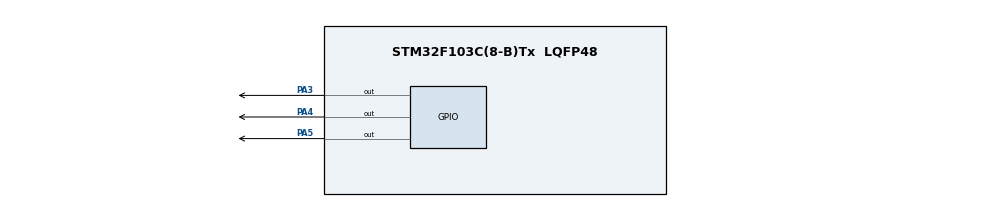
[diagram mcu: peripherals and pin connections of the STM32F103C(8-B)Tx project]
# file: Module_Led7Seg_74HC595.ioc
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Mcu.Family=STM32F1
Mcu.Name=STM32F103C(8-B)Tx
Mcu.Package=LQFP48
NVIC.PriorityGroup=NVIC_PRIORITYGROUP_4
PA13.Mode=Serial_Wire
PA13.Signal=SYS_JTMS-SWDIO
PA14.Mode=Serial_Wire
PA14.Signal=SYS_JTCK-SWCLK
PA3.Signal=GPIO_Output
PA4.Signal=GPIO_Output
PA5.Signal=GPIO_Output
ProjectManager.HeapSize=0x200
ProjectManager.StackSize=0x400
ProjectManager.TargetToolchain=STM32CubeIDE
RCC.APB1Freq_Value=8000000
RCC.APB2Freq_Value=8000000
board=custom

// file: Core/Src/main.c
/* USER CODE BEGIN Header */
/**
  ******************************************************************************
  * @file           : main.c
  * @brief          : Main program body
  ******************************************************************************
  * @attention
  *
  * Copyright (c) 2022 STMicroelectronics.
  * All rights reserved.
  *
  * This software is licensed under terms that can be found in the LICENSE file
  * in the root directory of this software component.
  * If no LICENSE file comes with this software, it is provided AS-IS.
  *
  ******************************************************************************
  */
/* USER CODE END Header */
#include "main.h"

/* USER CODE BEGIN PD */
#define CLK_GPIO GPIOA
#define CLK_PIN GPIO_PIN_3

#define LATCH_GPIO GPIOA
#define LATCH_PIN GPIO_PIN_4

#define DATA_GPIO GPIOA
#define DATA_PIN GPIO_PIN_5
/* USER CODE END PD */

void SystemClock_Config(void);
static void MX_GPIO_Init(void);

/* USER CODE BEGIN 0 */

int seg[10] = { 0x03, 0x9f, 0x25, 0x0D, 0x99, 0x49, 0x41, 0x1F, 0x01, 0x09 };
int seg_Dec[10] = { 0x02, 0x9E, 0x24, 0x0C, 0x98, 0x48, 0x40, 0x1E, 0x00, 0x08 };
int pos[8] = { 0x01, 0x02, 0x04, 0x08, 0x10, 0x20, 0x40, 0x80 };

void CLK()
{
	HAL_GPIO_WritePin(CLK_GPIO, CLK_PIN, GPIO_PIN_SET);
	HAL_GPIO_WritePin(CLK_GPIO, CLK_PIN, GPIO_PIN_RESET);
}

void LATCH()
{
	HAL_GPIO_WritePin(LATCH_GPIO, LATCH_PIN, GPIO_PIN_SET);
	HAL_GPIO_WritePin(LATCH_GPIO, LATCH_PIN, GPIO_PIN_RESET);
}

void DATA(int value)
{
	if(1==value)
	{
		HAL_GPIO_WritePin(DATA_GPIO, DATA_PIN, GPIO_PIN_SET);
	}
	else
	{
		HAL_GPIO_WritePin(DATA_GPIO, DATA_PIN, GPIO_PIN_RESET);
	}
	CLK();
}

void pushHEX(int hexValue)
{
	for (int i = 0; i < 8; i++) {
		if (hexValue & 0x01) {
			DATA(1);
		} else {
			DATA(0);
		}
		hexValue >>= 1;
	}
}

void shiftoutLed7Seg(int dataSeg, int position, int isDec) {
	position--;
	if (isDec == 1) {
		pushHEX(seg_Dec[dataSeg]);
		pushHEX(pos[position]);
		LATCH();
	} else {
		pushHEX(seg[dataSeg]);
		pushHEX(pos[position]);
		LATCH();
	}
}
/* USER CODE END 0 */

int main(void)
{

  /* MCU Configuration--------------------------------------------------------*/

  /* Reset of all peripherals, Initializes the Flash interface and the Systick. */
  HAL_Init();

  /* Configure the system clock */
  SystemClock_Config();

  /* Initialize all configured peripherals */
  MX_GPIO_Init();

  /* Infinite loop */
  /* USER CODE BEGIN WHILE */
  while (1)
  {
		shiftoutLed7Seg(2, 1, 0);
		shiftoutLed7Seg(7, 2, 0);
		shiftoutLed7Seg(1, 3, 0);
		shiftoutLed7Seg(0, 4, 0);
		shiftoutLed7Seg(2, 5, 0);
		shiftoutLed7Seg(0, 6, 0);
		shiftoutLed7Seg(0, 7, 0);
		shiftoutLed7Seg(0, 8, 0);
    /* USER CODE END WHILE */

  }
}

void SystemClock_Config(void)
{
  RCC_OscInitTypeDef RCC_OscInitStruct = {0};
  RCC_ClkInitTypeDef RCC_ClkInitStruct = {0};

  /** Initializes the RCC Oscillators according to the specified parameters
  * in the RCC_OscInitTypeDef structure.
  */
  RCC_OscInitStruct.OscillatorType = RCC_OSCILLATORTYPE_HSI;
  RCC_OscInitStruct.HSIState = RCC_HSI_ON;
  RCC_OscInitStruct.HSICalibrationValue = RCC_HSICALIBRATION_DEFAULT;
  RCC_OscInitStruct.PLL.PLLState = RCC_PLL_NONE;
  if (HAL_RCC_OscConfig(&RCC_OscInitStruct) != HAL_OK)
  {
    Error_Handler();
  }

  /** Initializes the CPU, AHB and APB buses clocks
  */
  RCC_ClkInitStruct.ClockType = RCC_CLOCKTYPE_HCLK|RCC_CLOCKTYPE_SYSCLK
                              |RCC_CLOCKTYPE_PCLK1|RCC_CLOCKTYPE_PCLK2;
  RCC_ClkInitStruct.SYSCLKSource = RCC_SYSCLKSOURCE_HSI;
  RCC_ClkInitStruct.AHBCLKDivider = RCC_SYSCLK_DIV1;
  RCC_ClkInitStruct.APB1CLKDivider = RCC_HCLK_DIV1;
  RCC_ClkInitStruct.APB2CLKDivider = RCC_HCLK_DIV1;

  if (HAL_RCC_ClockConfig(&RCC_ClkInitStruct, FLASH_LATENCY_0) != HAL_OK)
  {
    Error_Handler();
  }
}

static void MX_GPIO_Init(void)
{
  GPIO_InitTypeDef GPIO_InitStruct = {0};

  /* GPIO Ports Clock Enable */
  __HAL_RCC_GPIOA_CLK_ENABLE();

  /*Configure GPIO pin Output Level */
  HAL_GPIO_WritePin(GPIOA, GPIO_PIN_3|GPIO_PIN_4|GPIO_PIN_5, GPIO_PIN_RESET);

  /*Configure GPIO pins : PA3 PA4 PA5 */
  GPIO_InitStruct.Pin = GPIO_PIN_3|GPIO_PIN_4|GPIO_PIN_5;
  GPIO_InitStruct.Mode = GPIO_MODE_OUTPUT_PP;
  GPIO_InitStruct.Pull = GPIO_NOPULL;
  GPIO_InitStruct.Speed = GPIO_SPEED_FREQ_LOW;
  HAL_GPIO_Init(GPIOA, &GPIO_InitStruct);

}

void Error_Handler(void)
{
  __disable_irq();
  while (1)
  {
  }
}
